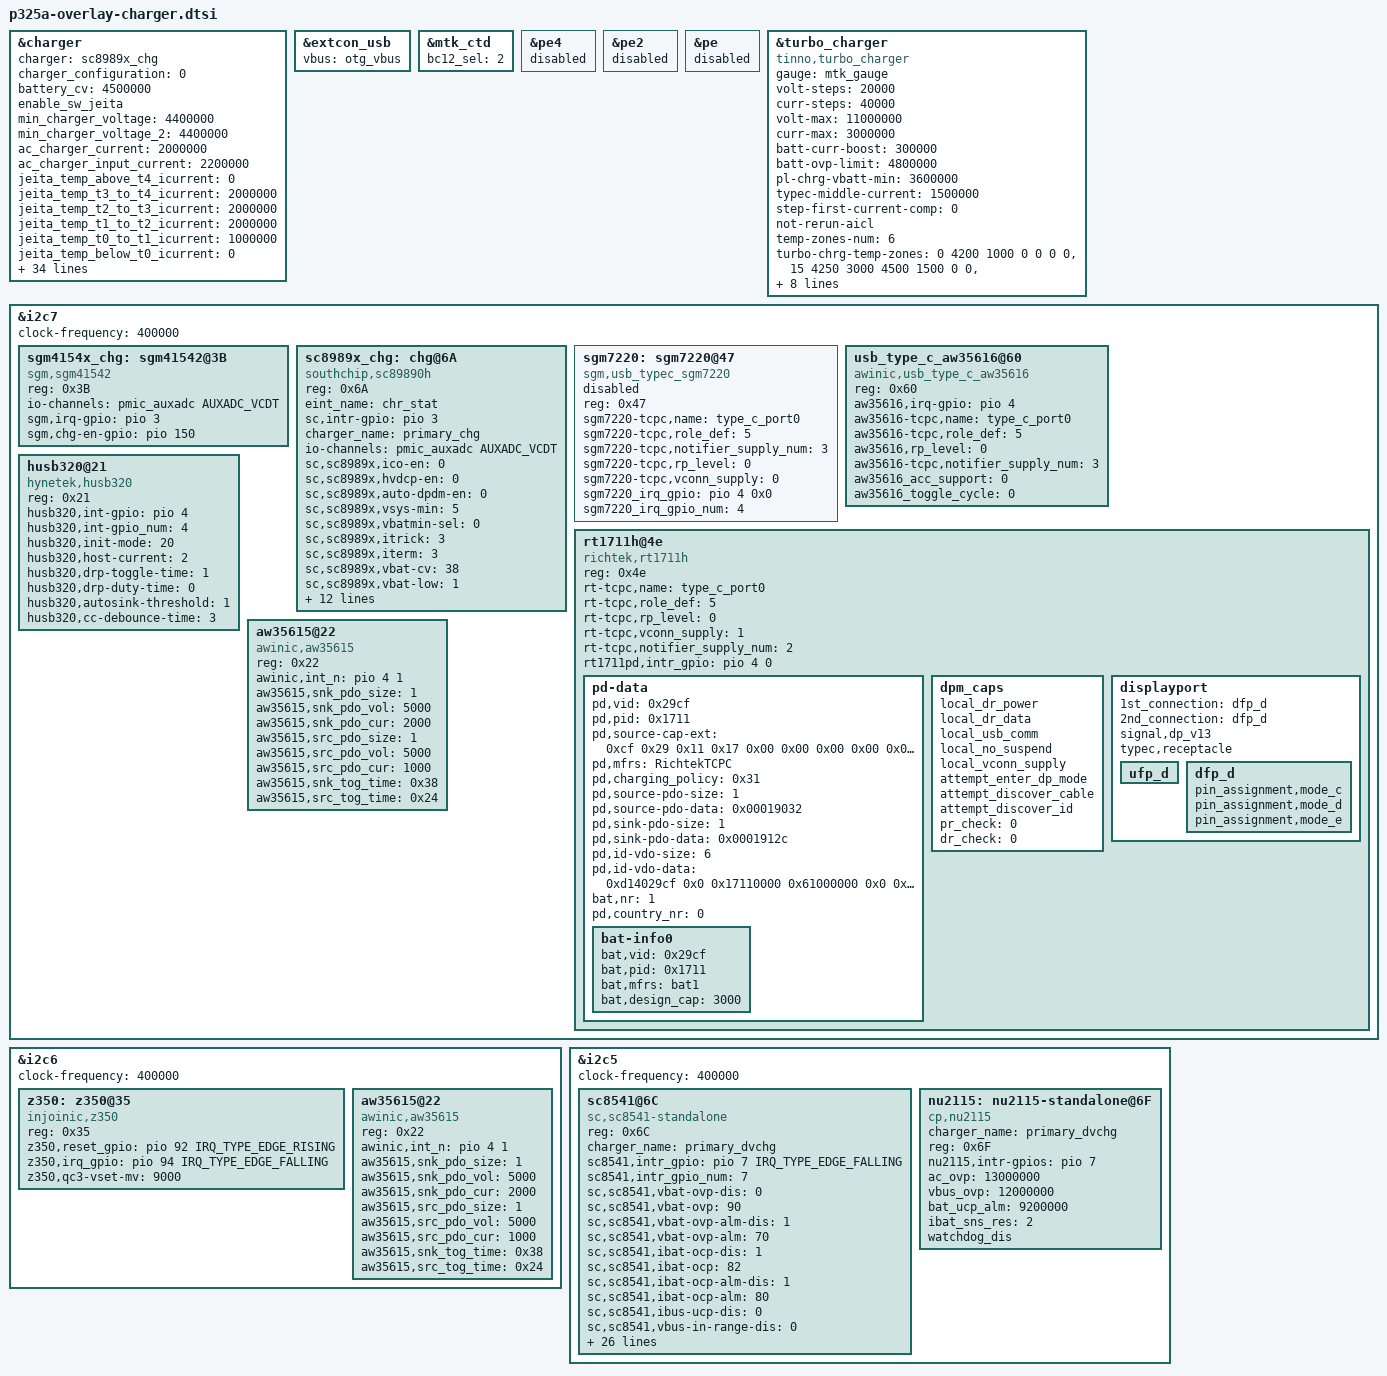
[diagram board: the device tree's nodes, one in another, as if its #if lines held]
/*[TN.NJDC] charger overlay file.start*/
#include <dt-bindings/iio/mt635x-auxadc.h>

&charger {
	charger = <&sc8989x_chg>;
	charger_configuration= <0>;
	battery_cv = <4500000>;
	enable_sw_jeita;
	min_charger_voltage = <4400000>;
	min_charger_voltage_2 = <4400000>;
	ac_charger_current = <2000000>;
	ac_charger_input_current = <2200000>;
	jeita_temp_above_t4_icurrent = <0>;
	jeita_temp_t3_to_t4_icurrent = <2000000>;
	jeita_temp_t2_to_t3_icurrent = <2000000>;
	jeita_temp_t1_to_t2_icurrent = <2000000>;
	jeita_temp_t0_to_t1_icurrent = <1000000>;
	jeita_temp_below_t0_icurrent = <0>;
	jeita_temp_above_t4_cv = <4200000>;
	jeita_temp_t3_to_t4_cv = <4200000>;
	jeita_temp_t2_to_t3_cv = <4500000>;
	jeita_temp_t1_to_t2_cv = <4500000>;
	jeita_temp_t0_to_t1_cv = <4200000>;
	jeita_temp_below_t0_cv = <4040000>;
	temp_t4_thres = <60>;
	temp_t4_thres_minus_x_degree = <57>;
	temp_t3_thres = <45>;
	temp_t3_thres_minus_x_degree = <42>;
	temp_t2_thres = <15>;
	temp_t2_thres_plus_x_degree = <18>;
	temp_t1_thres = <0>;
	temp_t1_thres_plus_x_degree = <3>;
	temp_t0_thres = <(-20)>;
	temp_t0_thres_plus_x_degree = <(-17)>;
	temp_neg_10_thres = <(-22)>;
	qc_temp_above_t4_icurrent = <0>;
	qc_temp_t3_to_t4_icurrent = <3600000>;
	qc_temp_t2_to_t3_icurrent = <3600000>;
	qc_temp_t1_to_t2_icurrent = <3600000>;
	qc_temp_t0_to_t1_icurrent = <1000000>;
	qc_temp_below_t0_icurrent = <0>;
	qc_input_current_limit = <3200000>;
	qc_charging_current_limit = <3600000>;
	max_charger_voltage = <11000000>;

	/* battery temperature protection */
	enable_min_charge_temp;
	min_charge_temp = <(-20)>;
	min_charge_temp_plus_x_degree = <(-17)>;
	max_charge_temp = <60>;
	max_charge_temp_minus_x_degree = <57>;

	/* ffc bat cfg */
	ffc-batt-zone = <0 4200 292>,
			<10 4500 292>,
			<15 4500 292>,
			<25 4530 600>,
			<35 4530 750>,
			<45 4530 800>,
			<60 4200 292>;
};

&extcon_usb {
	vbus = <&otg_vbus>;
};

&mtk_ctd {
	bc12_sel = <2>;
};

&pe4 {
	status = "disabled";
};

&pe2 {
	status = "disabled";
};

&pe {
	status = "disabled";
};

&turbo_charger {
	compatible = "tinno,turbo_charger";
	status = "okay";
	gauge = <&mtk_gauge>;

	volt-steps = <20000>; /*uV*/
	curr-steps = <40000>; /*uA*/
	volt-max = <11000000>; /*uV*/
	curr-max = <3000000>; /*uA*/
	batt-curr-boost = <300000>; /*uA*/
	batt-ovp-limit = <4800000>; /*uV*/
	pl-chrg-vbatt-min = <3600000>; /*uV*/
	typec-middle-current = <1500000>; /*uA*/
	step-first-current-comp = <0>;
	not-rerun-aicl;
	temp-zones-num = <6>;
	turbo-chrg-temp-zones = <0  4200 1000 0    0    0    0   >,
				<15 4250 3000 4500 1500 0    0   >,
				<25 4300 5800 4400 5200 4530 4000>,
				<35 4300 5800 4400 5200 4530 4000>,
				<45 4300 5800 4400 5200 4530 4000>,
				<60 4200 3000 0    0    0    0   >;
	thermal-min-level = <1500000>; /*uA*/
	sw-charging-curr-limited = <500000>; /*uA*/
	charging-curr-min = <2000000>; /*uA*/
	turbo-volt-comp = <300000>; /*uV*/
};

&i2c7 {
	sgm4154x_chg: sgm41542@3B {
		status = "okay";
		compatible = "sgm,sgm41542";
		reg = <0x3B>;
		io-channels = <&pmic_auxadc AUXADC_VCDT>;
		io-channel-names = "pmic_vbus";
		sgm,irq-gpio = <&pio 3 IRQ_TYPE_EDGE_FALLING>;     //irq num base on hardware design
		sgm,chg-en-gpio = <&pio 150 0>;   //gpio num base on hardware design  1.MTK parent node name is pio  2.QUALCOMM parent node name is tlmm or other
	};

	sc8989x_chg: chg@6A {
		compatible = "southchip,sc89890h";
		reg = <0x6A>;
		status = "okay";
		eint_name = "chr_stat";
		sc,intr-gpio = <&pio 3 IRQ_TYPE_EDGE_FALLING>;
		charger_name = "primary_chg";
		io-channels = <&pmic_auxadc AUXADC_VCDT>;
		io-channel-names = "pmic_vbus";
		sc,sc8989x,ico-en = <0>;
		sc,sc8989x,hvdcp-en = <0>;
		sc,sc8989x,auto-dpdm-en = <0>;
		sc,sc8989x,vsys-min = <5>; /*3500mV*/
		sc,sc8989x,vbatmin-sel = <0>; /*0:2.9V 1:2.5V*/
		sc,sc8989x,itrick = <3>; /*60 + val *60*/
		sc,sc8989x,iterm = <3>; /*30 + val * 60*/
		sc,sc8989x,vbat-cv = <38>; /*3840 + val * 16*/
		sc,sc8989x,vbat-low = <1>; /*0:2.8V 1:3V*/
		sc,sc8989x,vrechg = <0>; /*0:100mV 1:200mV*/
		sc,sc8989x,en-term = <1>;
		sc,sc8989x,stat-dis = <0>;
		sc,sc8989x,wd-time = <0>; /*0:Dis 1:40s 2:80s 3:160s*/
		sc,sc8989x,en-timer = <1>;
		sc,sc8989x,charge-timer = <2>; /*0:5h 1:8h 2:12h 3:20h*/
		sc,sc8989x,bat-comp = <0>; /*val * 20*/
		sc,sc8989x,vclamp = <0>; /*val *32*/
		sc,sc8989x,votg = <12>; /*3900 + val * 100*/
		sc,sc8989x,iboost = <7>; /*0:0.5A 3:1.4A 5:1.875A 7:2.45A*/
		sc,sc8989x,force_vindpm = <0>;
		sc,sc8989x,vindpm = <18>; /*2600 + val * 100*/
	};
};

&i2c6 {
/* TN Begin modified by wenfeng.qi/809603 20240920  */
	clock-frequency = <400000>;
	status = "okay";
	z350: z350@35 {
		compatible = "injoinic,z350";
		reg = <0x35>;
		z350,reset_gpio = <&pio 92 IRQ_TYPE_EDGE_RISING>;
		z350,irq_gpio = <&pio 94 IRQ_TYPE_EDGE_FALLING>;
		z350,qc3-vset-mv = <9000>;
		interrupt-names = "z350_irq";
		status = "okay";
	};
	aw35615@22 {
		compatible = "awinic,aw35615";
		reg = <0x22>;
		status = "okay";
		awinic,int_n = <&pio 4 1>;
		aw35615,snk_pdo_size = <1>; /* set sink pdo num*/
		aw35615,snk_pdo_vol = <5000>; /* set sink pdo voltage mV*/
		aw35615,snk_pdo_cur = <2000>; /* set sink pdo current mA*/
		aw35615,src_pdo_size = <1>; /* set source pdo num*/
		aw35615,src_pdo_vol = <5000>; /* set source pdo voltage mV*/
		aw35615,src_pdo_cur = <1000>; /* set source pdo current mA*/
		aw35615,snk_tog_time = <0x38>; /* set toggle sink time */
		aw35615,src_tog_time = <0x24>; /* set toggle source time */
	};
/* TN End modified by wenfeng.qi/809603 20240920 */
};

#ifdef CONFIG_DVT_BUILD
&i2c7 {
#else
&i2c6 {
#endif
	clock-frequency = <400000>;
	status = "okay";
	sgm7220: sgm7220@47 {
		compatible = "sgm,usb_typec_sgm7220";
		reg = <0x47>;
		status = "disabled";

		sgm7220-tcpc,name = "type_c_port0";    /* the name of tcpc_device */
		sgm7220-tcpc,role_def = <5>;           /* 0: TYPEC_ROLE_UNKNOWN,
                                                  1: TYPEC_ROLE_SNK,
                                                  2: TYPEC_ROLE_SRC,
                                                  3: TYPEC_ROLE_DRP,
                                                  4: TYPEC_ROLE_TRY_SRC,
                                                  5: TYPEC_ROLE_TRY_SNK */
		sgm7220-tcpc,notifier_supply_num = <3>;
		sgm7220-tcpc,rp_level = <0>;           /* 0: TYPEC_CC_RP_DFT,
                                                  1: TYPEC_CC_RP_1_5,
                                                  2: TYPEC_CC_RP_3_0 */
		sgm7220-tcpc,vconn_supply = <0>;       /* 0 : Default, 1: Always, 2:EMarkOnly, 3: StartOnly */
		sgm7220_irq_gpio = <&pio 4 0x0>;
		sgm7220_irq_gpio_num = <4>;
		pinctrl-names = "default";
        };

	usb_type_c_aw35616@60 {
 		status = "okay";
		compatible = "awinic,usb_type_c_aw35616";
		reg = <0x60>;
 		aw35616,irq-gpio = <&pio 4 0x0>;
		aw35616-tcpc,name = "type_c_port0";
		aw35616-tcpc,role_def = <5>; /* 1: SNK Only, 2: SRC Only, 3: DRP, 4: Try.SRC, 5: Try.SNK */
		aw35616,rp_level = <0>; /* 0: Default, 1: 1.5, 2: 3.0 */
		aw35616-tcpc,notifier_supply_num = <3>; /* the number of notifier supply */
		aw35616_acc_support = <0>; /* 0:support, 1:No support */
		aw35616_toggle_cycle = <0>; /* 0:Disable, 1:40ms, 2:80ms, 3:160ms */
	};

	rt1711h@4e {
		compatible = "richtek,rt1711h";
		reg = <0x4e>;
		status = "okay";
		rt-tcpc,name = "type_c_port0"; /* tcpc_device's name */
		rt-tcpc,role_def = <5>; /* 0: Unknown, 1: SNK, 2: SRC */
					/* 3: DRP, 4: Try.SRC, 5: Try.SNK */
		rt-tcpc,rp_level = <0>; /* 0: Default, 1: 1.5, 2: 3.0 */
		rt-tcpc,vconn_supply  = <1>;  /* 0: Never, 1: Always, */
					      /* 2: EMarkOnly, 3: StartOnly */
		rt-tcpc,notifier_supply_num = <2>;
		rt1711pd,intr_gpio = <&pio 4 0>;
		pd-data {
			pd,vid = <0x29cf>;
			pd,pid = <0x1711>;
			pd,source-cap-ext = /bits/ 8 <0xcf 0x29 0x11 0x17
						      0x00 0x00 0x00 0x00
						      0x00 0x00 0x00 0x00
						      0x00 0x00 0x00 0x00
						      0x00 0x00 0x00 0x00
						      0x00 0x00 0x01 0x02
						      0x00>;
			pd,mfrs = "RichtekTCPC";

			/*
			 *	VSAFE5V = 0, MAX_POWER = 1, CUSTOM = 2,
			 *	MAX_POWER_LV = 0x21, MAX_POWER_LVIC = 0x31
			 *	MAX_POWER_HV = 0x41, MAX_POWER_HVIC = 0x51
			 */
			pd,charging_policy= <0x31>;

			/*
			 * Fixed 5V, 500 mA <0x00019032>
			 * Fixed 5V, 1A <0x00019064>
			 * Fixed 5V, 2A <0x000190c8>
			 * Fixed 5V, 3A <0x0001912c>
			 * Fixed 9V, 500 mA <0x0002d032>
			 * Fixed 9V, 1A <0x0002d064>
			 * Fixed 9V, 2A <0x0002d0c8>
			 * Fixed 9V, 3A <0x0002d12c>
			 * Variable 5-9V, 1A <0x8642d064>
			 * Variable 5-9V, 2A <0x8642d0c8>
			 * Variable 5-9V, 3A <0x8642d12c>
			 * PPS 3V~5.9V, 3A <0xC0761E3C>
			 */
			pd,source-pdo-size = <1>;
			pd,source-pdo-data = <0x00019032>;
			pd,sink-pdo-size = <1>;
			//pd,sink-pdo-data = <0x000190c8 0x0002d0c8>;
			pd,sink-pdo-data = <0x0001912c>;

			/*
			 * No DP, host + device
			 *	pd,id-vdo-size = <6>;
			 *	pd,id-vdo-data = <0xd14029cf 0x0 0x17110000
						  0x61000000 0x0 0x41000000>;
			 * With DP
			 *	pd,id-vdo-size = <6>;
			 *	pd,id-vdo-data = <0xd54029cf 0x0 0x17110000
						  0x61000000 0x0 0x41000000>;
			 */

			pd,id-vdo-size = <6>;
			pd,id-vdo-data = <0xd14029cf 0x0 0x17110000
					  0x61000000 0x0 0x41000000>;

			bat,nr = <1>;
			pd,country_nr = <0>;

			bat-info0 {
				bat,vid = <0x29cf>;
				bat,pid = <0x1711>;
				bat,mfrs = "bat1";
				bat,design_cap = <3000>;
			};

			//bat-info1 {
			//	bat,vid = <0x8abc>;
			//	bat,pid = <0x5234>;
			//	bat,mfrs = "bat2";
			//	bat,design_cap = <4000>;
			//};

			//country0 {
			//	pd,country_code = <0x5457>;
			//	pd,country_len = <2>; /* max len = 26 */
			//	pd,country_data = <0xff 0xff>;
			//};

			//country1 {
			//	pd,country_code = <0x5553>;
			//	pd,country_len = <3>; /* max len = 26 */
			//	pd,country_data = <0xf1 0xf2 0xf3>;
			//};
		};
		dpm_caps {
			local_dr_power;
			local_dr_data;
			//local_ext_power;
			local_usb_comm;
			//local_usb_suspend;
			//local_high_cap;
			//local_give_back;
			local_no_suspend;
			local_vconn_supply;

			//attempt_discover_cable_dfp;
			attempt_enter_dp_mode;
			attempt_discover_cable;
			attempt_discover_id;

			/* 0: disable, 1: prefer_snk, 2: prefer_src */
			pr_check = <0>;
			//pr_reject_as_source;
			//pr_reject_as_sink;
			//pr_check_gp_source;
			//pr_check_gp_sink;

			/* 0: disable, 1: prefer_ufp, 2: prefer_dfp */
			dr_check = <0>;
			//dr_reject_as_dfp;
			//dr_reject_as_ufp;
		};
		displayport {
			/* connection type = "both", "ufp_d", "dfp_d" */
			1st_connection = "dfp_d";
			2nd_connection = "dfp_d";
			signal,dp_v13;
			//signal,dp_gen2;
			//usbr20_not_used;
			typec,receptacle;
			ufp_d {
				//pin_assignment,mode_a;
				//pin_assignment,mode_b;
				//pin_assignment,mode_c;
				//pin_assignment,mode_d;
				//pin_assignment,mode_e;
			};
			dfp_d {
				//pin_assignment,mode_a;
				//pin_assignment,mode_b;
				pin_assignment,mode_c;
				pin_assignment,mode_d;
				pin_assignment,mode_e;
				//pin_assignment,mode_f;
			};
		};
	};

	husb320@21 {
		status = "okay";
		compatible = "hynetek,husb320";
		reg = <0x21>;
		husb320,int-gpio = <&pio 4 0>;
		husb320,int-gpio_num = <4>;
		husb320,init-mode = <20>;                       /* try sink, DRP */
		husb320,host-current = <2>;                     /* 180uA host current */
		husb320,drp-toggle-time =  <1>;                 /* 70ms */
		husb320,drp-duty-time = <0>;                    /* 60 duty time */
		husb320,autosink-threshold = <1>;               /* 3P1V */
		husb320,cc-debounce-time = <3>;                 /* 150ms */
	};

	aw35615@22 {
		compatible = "awinic,aw35615";
		reg = <0x22>;
		status = "okay";
		awinic,int_n = <&pio 4 1>;
		aw35615,snk_pdo_size = <1>; /* set sink pdo num*/
		aw35615,snk_pdo_vol = <5000>; /* set sink pdo voltage mV*/
		aw35615,snk_pdo_cur = <2000>; /* set sink pdo current mA*/
		aw35615,src_pdo_size = <1>; /* set source pdo num*/
		aw35615,src_pdo_vol = <5000>; /* set source pdo voltage mV*/
		aw35615,src_pdo_cur = <1000>; /* set source pdo current mA*/
		aw35615,snk_tog_time = <0x38>; /* set toggle sink time */
		aw35615,src_tog_time = <0x24>; /* set toggle source time */
	};
};

#ifdef CONFIG_DVT_BUILD
&i2c5 {
#else
&i2c7 {
#endif
	clock-frequency = <400000>;
	sc8541@6C {
		compatible = "sc,sc8541-standalone";
		reg = <0x6C>;
		charger_name = "primary_dvchg";
		sc8541,intr_gpio = <&pio 7 IRQ_TYPE_EDGE_FALLING>;
		sc8541,intr_gpio_num = <7>;

		sc,sc8541,vbat-ovp-dis = <0>;
		sc,sc8541,vbat-ovp = <90>; /*3840 + val * 10*/
		sc,sc8541,vbat-ovp-alm-dis = <1>;
		sc,sc8541,vbat-ovp-alm = <70>; /*3840 + val * 10*/
		sc,sc8541,ibat-ocp-dis = <1>;
		sc,sc8541,ibat-ocp  = <82>; /*val * 100*/
		sc,sc8541,ibat-ocp-alm-dis = <1>;
		sc,sc8541,ibat-ocp-alm = <80>; /*val * 100*/
		sc,sc8541,ibus-ucp-dis = <0>;
		sc,sc8541,vbus-in-range-dis = <0>;
		sc,sc8541,vbus-pd-en = <0>;
		sc,sc8541,vbus-ovp = <80>; /*7000 + val * 50*/
		sc,sc8541,vbus-ovp-alm-dis = <1>;
		sc,sc8541,vbus-ovp-alm = <34>; /*7000 + val * 50*/
		sc,sc8541,ibus-ocp-dis = <0>;
		sc,sc8541,ibus-ocp = <13>; /*1000 + val * 250*/
		sc,sc8541,tshut-dis = <1>;
		sc,sc8541,tsbus-flt-dis = <1>;
		sc,sc8541,tsbat-flt-dis = <1>;
		sc,sc8541,tdie-alm = <200>; /*25 + val * 0.5*/
		sc,sc8541,tsbus-flt = <21>;
		sc,sc8541,tsbat-flt = <21>;
		sc,sc8541,vac1-ovp = <2>; /*0:6.5V 1:10.5V 2:12V 3:14V 4:16V 5~7:18V*/
		sc,sc8541,vac2-ovp = <2>; /*0:6.5V 1:10.5V 2:12V 3:14V 4:16V 5~7:18V*/
		sc,sc8541,vac1-pd-en = <0>;
		sc,sc8541,vac2-pd-en = <0>;
		sc,sc8541,fsw-set = <5>; /*0:200KHz 1:300KHz 2:400KHz
					3:500KHz 4:600KHz 5:650KHz 6:700KHz 7:750KHz*/
		sc,sc8541,wd-timeout = <0>; /*0:0.5s 1:1s 2:5s 3:30s*/
		sc,sc8541,wd-timeout-dis = <1>;
		sc,sc8541,ibat-sns-r = <0>; /*0:2mho 1:5mho*/
		sc,sc8541,ss-timeout = <7>; /*0:6.25ms 1:12.5ms 2:25ms 3:50ms
					4:100ms 5:400ms 6:1.5s 7:10s*/
		sc,sc8541,ibus-ucp-fall-dg = <1>;
		sc,sc8541,vout-ovp-dis = <0>;
		sc,sc8541,vout-ovp = <3>; /*4700 + val * 100*/
		sc,sc8541,pmid2out-uvp = <7>; /*50 + val * 25*/
		sc,sc8541,pmid2out-ovp = <7>; /*150 + val * 50*/
	};

	nu2115: nu2115-standalone@6F {
		compatible = "cp,nu2115";
		status = "okay";
		charger_name = "primary_dvchg";
		reg = <0x6F>;
		nu2115,intr-gpios = <&pio 7 0x0>;

		ac_ovp = <13000000>;
		vbus_ovp = <12000000>;
		bat_ucp_alm = <9200000>;
		ibat_sns_res = <2>;
		watchdog_dis;
	};
};
/*[TN.NJDC] charger overlay file.end*/
